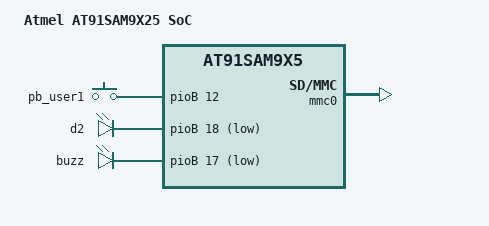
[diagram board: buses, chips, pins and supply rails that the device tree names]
/*
 * at91sam9x25.dtsi - Device Tree Include file for AT91SAM9X25 SoC
 *
 * Copyright (C) 2012 Jean-Christophe PLAGNIOL-VILLARD <plagnioj@jcrosoft.com>
 *
 * Licensed under GPLv2.
 */

/include/ "at91sam9x5.dtsi"

/ {
	model = "Atmel AT91SAM9X25 SoC";
	compatible = "atmel, at91sam9x25, atmel,at91sam9x5";

	ahb {
		apb {
			pinctrl@fffff400 {
				atmel,mux-mask = <
				      /*    A         B          C     */
				       0xffffffff 0xffe03fff 0xc000001c  /* pioA */
				       0x0007ffff 0x00047e3f 0x00000000  /* pioB */
				       0x80000000 0xfffd0000 0xb83fffff  /* pioC */
				       0x003fffff 0x003f8000 0x00000000  /* pioD */
				      >;
			};

			mmc0: mmc@f0008000 {
				pinctrl-0 = <&pinctrl_mmc0_clk_cmd_dat0 &pinctrl_mmc0_dat1_3 &pinctrl_mmc0_cd>;
				status = "okay";
				slot@0 {
					reg = <0>;
					bus-width = <4>;
					cd-gpios = <&pioD 15 0>;
				};
			};
		};
	};

	gpio_keys {
		compatible = "gpio-keys";
		#address-cells = <1>;
		#size-cells = <0>;

		pb_user1 {
			label = "pb_user1";
			gpios = <&pioB 12 0>;
			linux,code = <0x100>;
			gpio-key,wakeup;
		};
	};

	leds {
		compatible = "gpio-leds";

		d2 {
			label = "d2";
			gpios = <&pioB 18 1>;
			linux,default-trigger = "heartbeat";
		};

		buzz {
			label = "buzz";
			gpios = <&pioB 17 1>;
			status = "okay";
		};
	};
};
